VERSION ""

NS_ :

BS_:

BU_: Device Host

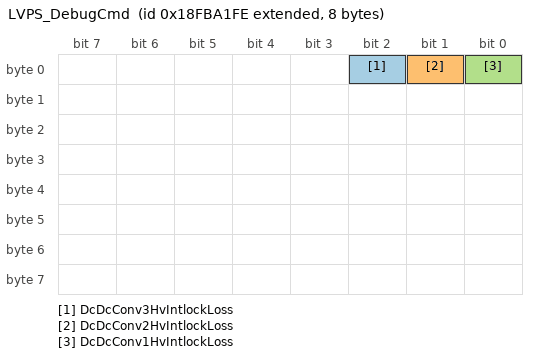
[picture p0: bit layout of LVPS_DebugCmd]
BO_ 2566627838 LVPS_DebugCmd: 8 Vector__XXX
 SG_ DcDcConv3HvIntlockLoss : 2|1@1+ (1,0) [0|0] "" Vector__XXX
 SG_ DcDcConv2HvIntlockLoss : 1|1@1+ (1,0) [0|0] "" Vector__XXX
 SG_ DcDcConv1HvIntlockLoss : 0|1@1+ (1,0) [0|0] "" Vector__XXX

CM_ "Arrival Low Voltage System Database.
$DBC storage: //depot/auto/dbc/Software_Modules/LV_System/LVSysDebug/ $
$Change: 0 $
$DateTime: 2020/11/18 22:30:00 $
$Revision: #1 $
$Author: lyamin@arrival.com $
Arrival LV Database";
BA_DEF_  "BusType" STRING ;
BA_DEF_  "DBName" STRING ;
BA_DEF_  "DatabaseVersion" STRING ;
BA_DEF_ BO_  "GenMsgCycleTime" INT 0 3600000;
BA_DEF_ BO_  "GenMsgILSupport" ENUM  "No","Yes";
BA_DEF_ BO_  "GenMsgRequestable" INT 0 1;
BA_DEF_ BO_  "GenMsgSendType" ENUM  "cyclic","NotUsed","NotUsed","NotUsed","NotUsed","NotUsed","NotUsed","IfActive","noMsgSendType";
BA_DEF_ SG_  "GenSigEVName" STRING ;
BA_DEF_ SG_  "GenSigILSupport" ENUM  "No","Yes";
BA_DEF_ SG_  "GenSigSendType" ENUM  "Cyclic","OnWrite","OnWriteWithRepetition","OnChange","OnChangeWithRepetition","IfActive","IfActiveWithRepetition","NoSigSendType";
BA_DEF_ BU_  "NmStationAddress" INT 0 255;
BA_DEF_  "ProtocolType" STRING ;
BA_DEF_  "SAE_J1939_21_SpecVersion" STRING ;
BA_DEF_  "SAE_J1939_71_SpecVersion" STRING ;
BA_DEF_  "SAE_J1939_73_SpecVersion" STRING ;
BA_DEF_  "SAE_J1939_75_SpecVersion" STRING ;
BA_DEF_  "SAE_J1939_81_SpecVersion" STRING ;
BA_DEF_  "SAE_J1939_DA_SpecVersion" STRING ;
BA_DEF_ SG_  "SigType" ENUM  "Default","Range","RangeSigned","ASCII","Discrete","Control","ReferencePGN","DTC","StringDelimiter","StringLength","StringLengthControl","MessageCounter","MessageChecksum";
BA_DEF_ BO_  "VFrameFormat" ENUM  "StandardCAN","ExtendedCAN","reserved","J1939PG","reserved","reserved","reserved","reserved","reserved","reserved","reserved","reserved","reserved","reserved","StandardCAN_FD","ExtendedCAN_FD";
BA_DEF_DEF_  "BusType" "";
BA_DEF_DEF_  "DBName" "";
BA_DEF_DEF_  "DatabaseVersion" "";
BA_DEF_DEF_  "GenMsgCycleTime" 0;
BA_DEF_DEF_  "GenMsgILSupport" "Yes";
BA_DEF_DEF_  "GenMsgRequestable" 1;
BA_DEF_DEF_  "GenMsgSendType" "noMsgSendType";
BA_DEF_DEF_  "GenSigEVName" "Env@Nodename_@Signame";
BA_DEF_DEF_  "GenSigILSupport" "Yes";
BA_DEF_DEF_  "GenSigSendType" "NoSigSendType";
BA_DEF_DEF_  "NmStationAddress" 254;
BA_DEF_DEF_  "ProtocolType" "";
BA_DEF_DEF_  "SAE_J1939_21_SpecVersion" "";
BA_DEF_DEF_  "SAE_J1939_71_SpecVersion" "";
BA_DEF_DEF_  "SAE_J1939_73_SpecVersion" "";
BA_DEF_DEF_  "SAE_J1939_75_SpecVersion" "";
BA_DEF_DEF_  "SAE_J1939_81_SpecVersion" "";
BA_DEF_DEF_  "SAE_J1939_DA_SpecVersion" "";
BA_DEF_DEF_  "SigType" "Default";
BA_DEF_DEF_  "VFrameFormat" "J1939PG";
BA_ "SAE_J1939_DA_SpecVersion" "2015-01";
BA_ "SAE_J1939_81_SpecVersion" "2012-05";
BA_ "SAE_J1939_75_SpecVersion" "2012-05";
BA_ "SAE_J1939_73_SpecVersion" "2012-10";
BA_ "SAE_J1939_71_SpecVersion" "2012-10";
BA_ "SAE_J1939_21_SpecVersion" "2006-10";
BA_ "ProtocolType" "J1939";
BA_ "DatabaseVersion" "1.0";
BA_ "BusType" "CAN";
BA_ "DBName" "LV";
BA_ "GenMsgCycleTime" BO_ 2566627838 100;
BA_ "GenMsgSendType" BO_ 2566627838 0;
